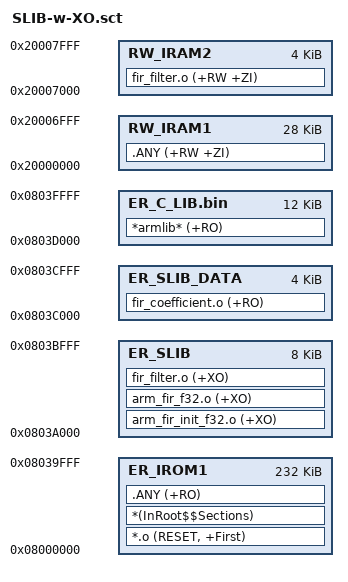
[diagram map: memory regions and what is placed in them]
; *************************************************************
; *** Scatter-Loading Description File generated by uVision ***
; *************************************************************

; This Scatter file is used for AT32F415RCT7 ( flash size is 256KB, page size is 2KB)

LR_IROM1 0x08000000 0x0003A000  {    ; user code area
  ER_IROM1 0x08000000 0x0003A000  { 
    *.o (RESET, +First)
    *(InRoot$$Sections)
    .ANY (+RO)		
  }
  
  RW_IRAM1 0x20000000 0x00007000  {  ; user RAM area
    .ANY (+RW +ZI)
  }
 
   
  RW_IRAM2 0x20007000 0x00001000  {  ; RAM used for sLIB code
    fir_filter.o (+RW +ZI) 
  }  
  
}

LR_SLIB 0x0803A000 0x0002000  {      ; sLib code
  ER_SLIB 0x0803A000 0x00002000  {  
    
	arm_fir_init_f32.o (+XO)
	arm_fir_f32.o (+XO)
	fir_filter.o (+XO)
   
  }
}

LR_SLIB_DATA 0x0803C000 0x00001000  {    ; sLib data
  ER_SLIB_DATA 0x0803C000 0x00001000  {  
 
   fir_coefficient.o (+RO)   
  }
}

LR_C_LIB 0x0803D000 0x00003000  {        
  ER_C_LIB.bin 0x0803D000 0x00003000  {  
	*armlib* (+RO)                       ; C and sowtware floating point library
  }
}

 


